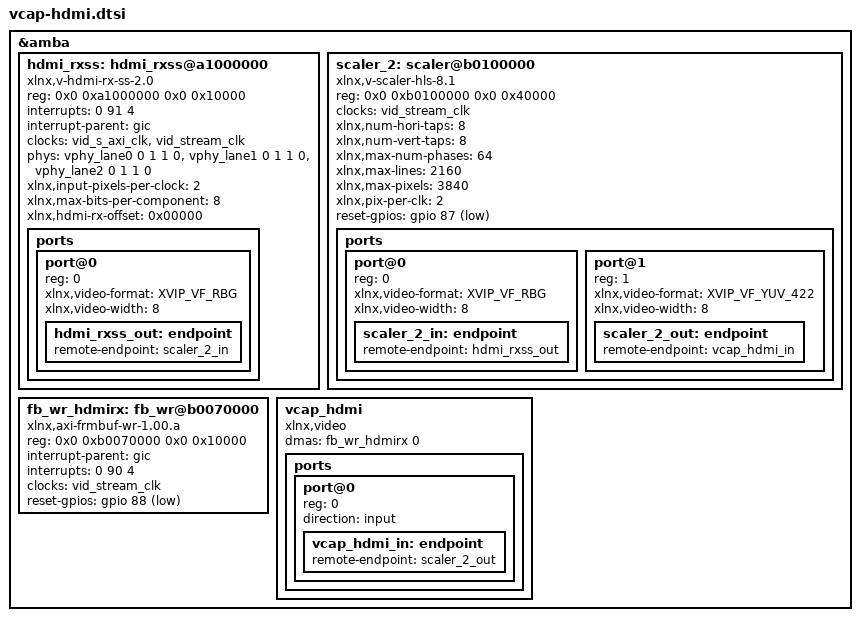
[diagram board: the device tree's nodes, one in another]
#include <dt-bindings/media/xilinx-vip.h>

&amba {
	hdmi_rxss: hdmi_rxss@a1000000 {
		compatible = "xlnx,v-hdmi-rx-ss-2.0";
		reg = <0x0 0xa1000000 0x0 0x10000>;
		interrupts = <0 91 4>;
		interrupt-parent = <&gic>;
		clocks = <&vid_s_axi_clk>, <&vid_stream_clk>;
		clock-names = "axi-lite", "video";
		phy-names = "hdmi-phy0", "hdmi-phy1", "hdmi-phy2";
		phys = <&vphy_lane0 0 1 1 0>, <&vphy_lane1 0 1 1 0>, <&vphy_lane2 0 1 1 0>;

		xlnx,input-pixels-per-clock = <2>;
		xlnx,max-bits-per-component = <8>;
		xlnx,hdmi-rx-offset = <0x00000>;

		ports {
			#address-cells = <1>;
			#size-cells = <0>;

			port@0 {
				reg = <0>;

				xlnx,video-format = <XVIP_VF_RBG>;
				xlnx,video-width = <8>;

				hdmi_rxss_out: endpoint {
					remote-endpoint = <&scaler_2_in>;
				};
			};
		};
	};

	scaler_2: scaler@b0100000 {
		compatible = "xlnx,v-scaler-hls-8.1";
		reg = <0x0 0xb0100000 0x0 0x40000>;
		clocks = <&vid_stream_clk>;

		xlnx,num-hori-taps = <8>;
		xlnx,num-vert-taps = <8>;
		xlnx,max-num-phases = <64>;
		xlnx,max-lines = <2160>;
		xlnx,max-pixels = <3840>;
		xlnx,pix-per-clk = <2>;

		reset-gpios = <&gpio 87 1>;

		ports {
			#address-cells = <1>;
			#size-cells = <0>;

			port@0 {
				reg = <0>;

				xlnx,video-format = <XVIP_VF_RBG>;
				xlnx,video-width = <8>;

				scaler_2_in: endpoint {
					remote-endpoint = <&hdmi_rxss_out>;
				};
			};
			port@1 {
				reg = <1>;

				xlnx,video-format = <XVIP_VF_YUV_422>;
				xlnx,video-width = <8>;

				scaler_2_out: endpoint {
					remote-endpoint = <&vcap_hdmi_in>;
				};
			};
		};
	};

	fb_wr_hdmirx: fb_wr@b0070000 {
		compatible = "xlnx,axi-frmbuf-wr-1.00.a";
		reg = <0x0 0xb0070000 0x0 0x10000>;
		#dma-cells = <1>;
		interrupt-parent = <&gic>;
		interrupts = <0 90 4>;
		clocks = <&vid_stream_clk>;
		clock-names = "axis";
		reset-gpios = <&gpio 88 1>;
	};

	vcap_hdmi {
		compatible = "xlnx,video";
		dmas = <&fb_wr_hdmirx 0>;
		dma-names = "port0";

		ports {
			#address-cells = <1>;
			#size-cells = <0>;

			port@0 {
				reg = <0>;
				direction = "input";
				vcap_hdmi_in: endpoint {
					remote-endpoint = <&scaler_2_out>;
				};
			};
		};
	};
};
